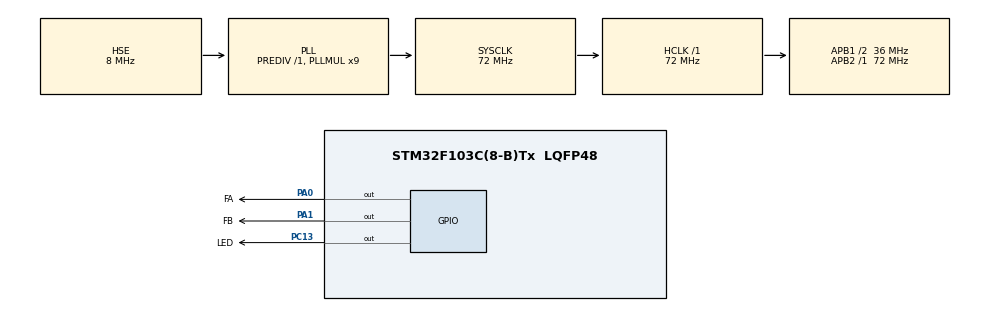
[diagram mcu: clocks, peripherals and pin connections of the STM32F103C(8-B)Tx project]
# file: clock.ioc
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Mcu.Family=STM32F1
Mcu.Name=STM32F103C(8-B)Tx
Mcu.Package=LQFP48
NVIC.PriorityGroup=NVIC_PRIORITYGROUP_4
NVIC.TIM1_UP_IRQn=true\:0\:0\:false\:false\:true\:true\:true
NVIC.TIM2_IRQn=true\:0\:0\:false\:false\:true\:true\:true
PA0-WKUP.GPIO_Label=FA
PA0-WKUP.GPIO_Speed=GPIO_SPEED_FREQ_HIGH
PA0-WKUP.Signal=GPIO_Output
PA1.GPIO_Label=FB
PA1.GPIO_Speed=GPIO_SPEED_FREQ_HIGH
PA1.PinState=GPIO_PIN_SET
PA1.Signal=GPIO_Output
PA13.Mode=Serial_Wire
PA13.Signal=SYS_JTMS-SWDIO
PA14.Mode=Serial_Wire
PA14.Signal=SYS_JTCK-SWCLK
PC13-TAMPER-RTC.GPIO_Label=LED
PC13-TAMPER-RTC.GPIO_Speed=GPIO_SPEED_FREQ_HIGH
PC13-TAMPER-RTC.Signal=GPIO_Output
PD0-OSC_IN.Mode=HSE-External-Oscillator
PD0-OSC_IN.Signal=RCC_OSC_IN
PD1-OSC_OUT.Mode=HSE-External-Oscillator
PD1-OSC_OUT.Signal=RCC_OSC_OUT
ProjectManager.HeapSize=0x200
ProjectManager.StackSize=0x400
ProjectManager.TargetToolchain=STM32CubeIDE
RCC.AHBFreq_Value=72000000
RCC.APB1CLKDivider=RCC_HCLK_DIV2
RCC.APB1Freq_Value=36000000
RCC.APB1TimFreq_Value=72000000
RCC.APB2Freq_Value=72000000
RCC.APB2TimFreq_Value=72000000
RCC.HCLKFreq_Value=72000000
RCC.PLLMUL=RCC_PLL_MUL9
RCC.PLLSourceVirtual=RCC_PLLSOURCE_HSE
RCC.SYSCLKFreq_VALUE=72000000
RCC.SYSCLKSource=RCC_SYSCLKSOURCE_PLLCLK
RCC.USBFreq_Value=72000000
TIM1.AutoReloadPreload=TIM_AUTORELOAD_PRELOAD_DISABLE
TIM1.ClockDivision=TIM_CLOCKDIVISION_DIV1
TIM1.Period=89
TIM1.Prescaler=39
TIM1.RepetitionCounter=0
TIM1.TIM_MasterOutputTrigger=TIM_TRGO_UPDATE
TIM2.AutoReloadPreload=TIM_AUTORELOAD_PRELOAD_DISABLE
TIM2.Period=89
TIM2.Prescaler=39
TIM2.TIM_MasterOutputTrigger=TIM_TRGO_UPDATE
VP_TIM1_VS_ClockSourceINT.Mode=Internal
VP_TIM2_VS_ClockSourceINT.Mode=Internal
board=custom

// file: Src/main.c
/* USER CODE BEGIN Header */
/**
  ******************************************************************************
  Gerador de clock utilizando 2 timer para gerar duas frequências
  Autor: Eng. Fabrício Ribeiro
  Data: 07/10/19
  ******************************************************************************
  */
/* USER CODE END Header */

#include "main.h"

TIM_HandleTypeDef htim1;
TIM_HandleTypeDef htim2;

void SystemClock_Config(void);
static void MX_GPIO_Init(void);
static void MX_TIM1_Init(void);
static void MX_TIM2_Init(void);

int main(void)
{

  /* MCU Configuration--------------------------------------------------------*/

  /* Reset of all peripherals, Initializes the Flash interface and the Systick. */
  HAL_Init();

  /* Configure the system clock */
  SystemClock_Config();

  /* Initialize all configured peripherals */
  MX_GPIO_Init();
  MX_TIM1_Init();
  MX_TIM2_Init();
  /* USER CODE BEGIN 2 */
  HAL_TIM_Base_Start_IT(&htim1);
  HAL_TIM_Base_Start_IT(&htim2);

  /* USER CODE END 2 */

  /* Infinite loop */
  /* USER CODE BEGIN WHILE */
  while (1)
  {
	  //https://www.youtube.com/watch?v=R8UwAboFQGA

	HAL_GPIO_WritePin(LED_GPIO_Port, LED_Pin, 0);
	HAL_Delay(50);
	HAL_GPIO_WritePin(LED_GPIO_Port, LED_Pin, 1);
	HAL_Delay(50);
	HAL_GPIO_WritePin(LED_GPIO_Port, LED_Pin, 0);
	HAL_Delay(50);
	HAL_GPIO_WritePin(LED_GPIO_Port, LED_Pin, 1);
	HAL_Delay(50);
	HAL_GPIO_WritePin(LED_GPIO_Port, LED_Pin, 0);
	HAL_Delay(50);
	HAL_GPIO_WritePin(LED_GPIO_Port, LED_Pin, 1);
	HAL_Delay(3000);
    /* USER CODE END WHILE */

    /* USER CODE BEGIN 3 */
	//HAL_GPIO_WritePin(GPIOC, GPIO_PIN_13, GPIO_PIN_RESET);

  }
  /* USER CODE END 3 */
}

void SystemClock_Config(void)
{
  RCC_OscInitTypeDef RCC_OscInitStruct = {0};
  RCC_ClkInitTypeDef RCC_ClkInitStruct = {0};

  /** Initializes the CPU, AHB and APB busses clocks
  */
  RCC_OscInitStruct.OscillatorType = RCC_OSCILLATORTYPE_HSE;
  RCC_OscInitStruct.HSEState = RCC_HSE_ON;
  RCC_OscInitStruct.HSEPredivValue = RCC_HSE_PREDIV_DIV1;
  RCC_OscInitStruct.HSIState = RCC_HSI_ON;
  RCC_OscInitStruct.PLL.PLLState = RCC_PLL_ON;
  RCC_OscInitStruct.PLL.PLLSource = RCC_PLLSOURCE_HSE;
  RCC_OscInitStruct.PLL.PLLMUL = RCC_PLL_MUL9;
  if (HAL_RCC_OscConfig(&RCC_OscInitStruct) != HAL_OK)
  {
    Error_Handler();
  }
  /** Initializes the CPU, AHB and APB busses clocks
  */
  RCC_ClkInitStruct.ClockType = RCC_CLOCKTYPE_HCLK|RCC_CLOCKTYPE_SYSCLK
                              |RCC_CLOCKTYPE_PCLK1|RCC_CLOCKTYPE_PCLK2;
  RCC_ClkInitStruct.SYSCLKSource = RCC_SYSCLKSOURCE_PLLCLK;
  RCC_ClkInitStruct.AHBCLKDivider = RCC_SYSCLK_DIV1;
  RCC_ClkInitStruct.APB1CLKDivider = RCC_HCLK_DIV2;
  RCC_ClkInitStruct.APB2CLKDivider = RCC_HCLK_DIV1;

  if (HAL_RCC_ClockConfig(&RCC_ClkInitStruct, FLASH_LATENCY_2) != HAL_OK)
  {
    Error_Handler();
  }
}

static void MX_TIM1_Init(void)
{

  TIM_ClockConfigTypeDef sClockSourceConfig = {0};
  TIM_MasterConfigTypeDef sMasterConfig = {0};

  htim1.Instance = TIM1;
  htim1.Init.Prescaler = 39;
  htim1.Init.CounterMode = TIM_COUNTERMODE_UP;
  htim1.Init.Period = 89;
  htim1.Init.ClockDivision = TIM_CLOCKDIVISION_DIV1;
  htim1.Init.RepetitionCounter = 0;
  htim1.Init.AutoReloadPreload = TIM_AUTORELOAD_PRELOAD_DISABLE;
  if (HAL_TIM_Base_Init(&htim1) != HAL_OK)
  {
    Error_Handler();
  }
  sClockSourceConfig.ClockSource = TIM_CLOCKSOURCE_INTERNAL;
  if (HAL_TIM_ConfigClockSource(&htim1, &sClockSourceConfig) != HAL_OK)
  {
    Error_Handler();
  }
  sMasterConfig.MasterOutputTrigger = TIM_TRGO_UPDATE;
  sMasterConfig.MasterSlaveMode = TIM_MASTERSLAVEMODE_DISABLE;
  if (HAL_TIMEx_MasterConfigSynchronization(&htim1, &sMasterConfig) != HAL_OK)
  {
    Error_Handler();
  }

}

static void MX_TIM2_Init(void)
{

  TIM_ClockConfigTypeDef sClockSourceConfig = {0};
  TIM_MasterConfigTypeDef sMasterConfig = {0};

  htim2.Instance = TIM2;
  htim2.Init.Prescaler = 39;
  htim2.Init.CounterMode = TIM_COUNTERMODE_UP;
  htim2.Init.Period = 89;
  htim2.Init.ClockDivision = TIM_CLOCKDIVISION_DIV1;
  htim2.Init.AutoReloadPreload = TIM_AUTORELOAD_PRELOAD_DISABLE;
  if (HAL_TIM_Base_Init(&htim2) != HAL_OK)
  {
    Error_Handler();
  }
  sClockSourceConfig.ClockSource = TIM_CLOCKSOURCE_INTERNAL;
  if (HAL_TIM_ConfigClockSource(&htim2, &sClockSourceConfig) != HAL_OK)
  {
    Error_Handler();
  }
  sMasterConfig.MasterOutputTrigger = TIM_TRGO_UPDATE;
  sMasterConfig.MasterSlaveMode = TIM_MASTERSLAVEMODE_DISABLE;
  if (HAL_TIMEx_MasterConfigSynchronization(&htim2, &sMasterConfig) != HAL_OK)
  {
    Error_Handler();
  }

}

static void MX_GPIO_Init(void)
{
  GPIO_InitTypeDef GPIO_InitStruct = {0};

  /* GPIO Ports Clock Enable */
  __HAL_RCC_GPIOC_CLK_ENABLE();
  __HAL_RCC_GPIOD_CLK_ENABLE();
  __HAL_RCC_GPIOA_CLK_ENABLE();

  /*Configure GPIO pin Output Level */
  HAL_GPIO_WritePin(LED_GPIO_Port, LED_Pin, GPIO_PIN_RESET);

  /*Configure GPIO pin Output Level */
  HAL_GPIO_WritePin(FA_GPIO_Port, FA_Pin, GPIO_PIN_RESET);

  /*Configure GPIO pin Output Level */
  HAL_GPIO_WritePin(FB_GPIO_Port, FB_Pin, GPIO_PIN_SET);

  /*Configure GPIO pin : LED_Pin */
  GPIO_InitStruct.Pin = LED_Pin;
  GPIO_InitStruct.Mode = GPIO_MODE_OUTPUT_PP;
  GPIO_InitStruct.Pull = GPIO_NOPULL;
  GPIO_InitStruct.Speed = GPIO_SPEED_FREQ_HIGH;
  HAL_GPIO_Init(LED_GPIO_Port, &GPIO_InitStruct);

  /*Configure GPIO pins : FA_Pin FB_Pin */
  GPIO_InitStruct.Pin = FA_Pin|FB_Pin;
  GPIO_InitStruct.Mode = GPIO_MODE_OUTPUT_PP;
  GPIO_InitStruct.Pull = GPIO_NOPULL;
  GPIO_InitStruct.Speed = GPIO_SPEED_FREQ_HIGH;
  HAL_GPIO_Init(GPIOA, &GPIO_InitStruct);

}

/* USER CODE BEGIN 4 */

void HAL_TIM_PeriodElapsedCallback(TIM_HandleTypeDef *htim)
{

	if (htim->Instance == htim1.Instance)
    {
		//10kHz no timer2
		HAL_GPIO_TogglePin(GPIOA, FA_Pin);
    }
	else if (htim->Instance == htim2.Instance)
    {
		//10kHz no timer1
		HAL_GPIO_TogglePin(GPIOA, FB_Pin);
    }
}

/* USER CODE END 4 */

void Error_Handler(void)
{
}

/************************ (C) COPYRIGHT STMicroelectronics *****END OF FILE****/
